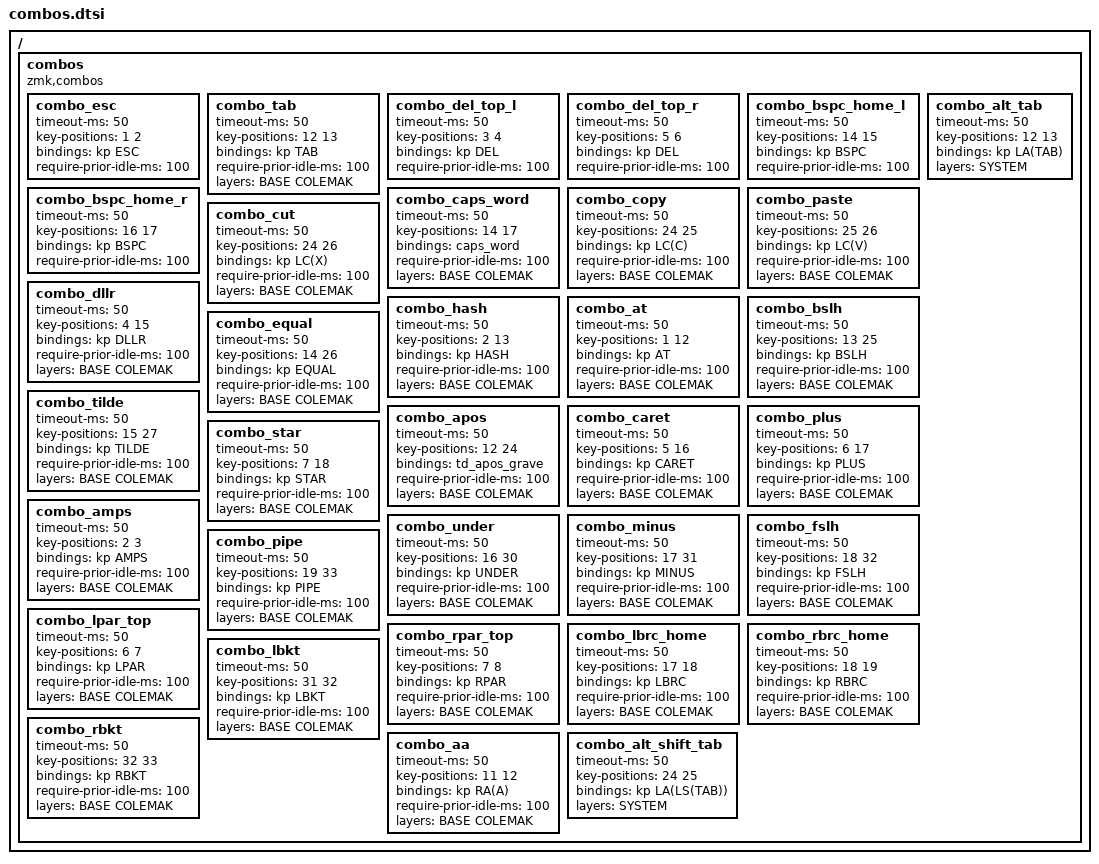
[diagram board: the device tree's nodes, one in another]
/*
 * Combo definitions for the KLOR keymap.
 * Include this file in klor.keymap via: #include "combos.dtsi"
 *
 * Key position map:
 *
 *  ┌─────┬─────┬─────┬─────┬─────┐                       ┌─────┬─────┬─────┬─────┬─────┐
 *  │  0  │  1  │  2  │  3  │  4  │                       │  5  │  6  │  7  │  8  │  9  │
 *  ├─────┼─────┼─────┼─────┼─────┤                       ├─────┼─────┼─────┼─────┼─────┤
 *  │ 11  │ 12  │ 13  │ 14  │ 15  │                       │ 16  │ 17  │ 18  │ 19  │ 20  │
 *  ├─────┼─────┼─────┼─────┼─────┼─────┐         ┌─────┼─────┼─────┼─────┼─────┼─────┤
 *  │ 23  │ 24  │ 25  │ 26  │ 27  │ 28  │         │ 29  │ 30  │ 31  │ 32  │ 33  │ 34  │
 *  └─────┴─────┴─────┼─────┼─────┼─────┘         └─────┼─────┼─────┼─────┴─────┴─────┘
 *                    │ 36  │ 37  │ 38  │ 39  40  │ 41  │ 42  │ 43  │
 *                    └─────┴─────┴─────┴─────────┴─────┴─────┴─────┘
 *
 * Note: outer pinky columns (10, 21, 22, 35) are &trans in all layers and excluded here.
 *
 * Layer policy:
 *   - ESC, BSPC, DEL combos are active on ALL layers (no layers restriction).
 *   - All other combos are BASE + COLEMAK (layers = <BASE COLEMAK>).
 */

/ {
    combos {
        compatible = "zmk,combos";

        // ── Navigation ─────────────────────────────────────────────────────────
        // W + E  →  Escape  [all layers]
        combo_esc {
            timeout-ms = <50>;
            key-positions = <1 2>;
            bindings = <&kp ESC>;
            require-prior-idle-ms = <100>;
        };

        // S + D  →  Tab  [BASE only]
        combo_tab {
            timeout-ms = <50>;
            key-positions = <12 13>;
            bindings = <&kp TAB>;
            require-prior-idle-ms = <100>;
            layers = <BASE COLEMAK>;
        };

        // R + T  →  Delete  [all layers]
        combo_del_top_l {
            timeout-ms = <50>;
            key-positions = <3 4>;
            bindings = <&kp DEL>;
            require-prior-idle-ms = <100>;
        };

        // Y + U  →  Delete  [all layers]
        combo_del_top_r {
            timeout-ms = <50>;
            key-positions = <5 6>;
            bindings = <&kp DEL>;
            require-prior-idle-ms = <100>;
        };

        // F + G  →  Backspace  [all layers]
        combo_bspc_home_l {
            timeout-ms = <50>;
            key-positions = <14 15>;
            bindings = <&kp BSPC>;
            require-prior-idle-ms = <100>;
        };

        // H + J  →  Backspace  [all layers]
        combo_bspc_home_r {
            timeout-ms = <50>;
            key-positions = <16 17>;
            bindings = <&kp BSPC>;
            require-prior-idle-ms = <100>;
        };

        // F + J  →  Caps Word  [BASE only]
        combo_caps_word {
            timeout-ms = <50>;
            key-positions = <14 17>;
            bindings = <&caps_word>;
            require-prior-idle-ms = <100>;
            layers = <BASE COLEMAK>;
        };

        // ── Clipboard ──────────────────────────────────────────────────────────
        // X + C  →  Copy  [BASE only]
        combo_copy {
            timeout-ms = <50>;
            key-positions = <24 25>;
            bindings = <&kp LC(C)>;
            require-prior-idle-ms = <100>;
            layers = <BASE COLEMAK>;
        };

        // C + V  →  Paste  [BASE only]
        combo_paste {
            timeout-ms = <50>;
            key-positions = <25 26>;
            bindings = <&kp LC(V)>;
            require-prior-idle-ms = <100>;
            layers = <BASE COLEMAK>;
        };

        // X + V  →  Cut  [BASE only]
        combo_cut {
            timeout-ms = <50>;
            key-positions = <24 26>;
            bindings = <&kp LC(X)>;
            require-prior-idle-ms = <100>;
            layers = <BASE COLEMAK>;
        };

        // ── Symbols: left side vertical (top → home) ───────────────────────────
        // T + G  →  $  [BASE only]
        combo_dllr {
            timeout-ms = <50>;
            key-positions = <4 15>;
            bindings = <&kp DLLR>;
            require-prior-idle-ms = <100>;
            layers = <BASE COLEMAK>;
        };

        // E + D  →  #  [BASE only]
        combo_hash {
            timeout-ms = <50>;
            key-positions = <2 13>;
            bindings = <&kp HASH>;
            require-prior-idle-ms = <100>;
            layers = <BASE COLEMAK>;
        };

        // W + S  →  @  [BASE only]
        combo_at {
            timeout-ms = <50>;
            key-positions = <1 12>;
            bindings = <&kp AT>;
            require-prior-idle-ms = <100>;
            layers = <BASE COLEMAK>;
        };

        // ── Symbols: left side vertical (home → bottom) ───────────────────────
        // D + C  →  backslash  [BASE only]
        combo_bslh {
            timeout-ms = <50>;
            key-positions = <13 25>;
            bindings = <&kp BSLH>;
            require-prior-idle-ms = <100>;
            layers = <BASE COLEMAK>;
        };

        // F + V  →  =  [BASE only]
        combo_equal {
            timeout-ms = <50>;
            key-positions = <14 26>;
            bindings = <&kp EQUAL>;
            require-prior-idle-ms = <100>;
            layers = <BASE COLEMAK>;
        };

        // G + B  →  ~  [BASE only]
        combo_tilde {
            timeout-ms = <50>;
            key-positions = <15 27>;
            bindings = <&kp TILDE>;
            require-prior-idle-ms = <100>;
            layers = <BASE COLEMAK>;
        };

        // S + X  →  ' (tap) / ` (double-tap)  [BASE only]
        combo_apos {
            timeout-ms = <50>;
            key-positions = <12 24>;
            bindings = <&td_apos_grave>;
            require-prior-idle-ms = <100>;
            layers = <BASE COLEMAK>;
        };

        // ── Symbols: right side vertical (top → home) ─────────────────────────
        // Y + H  →  ^  [BASE only]
        combo_caret {
            timeout-ms = <50>;
            key-positions = <5 16>;
            bindings = <&kp CARET>;
            require-prior-idle-ms = <100>;
            layers = <BASE COLEMAK>;
        };

        // U + J  →  +  [BASE only]
        combo_plus {
            timeout-ms = <50>;
            key-positions = <6 17>;
            bindings = <&kp PLUS>;
            require-prior-idle-ms = <100>;
            layers = <BASE COLEMAK>;
        };

        // I + K  →  *  [BASE only]
        combo_star {
            timeout-ms = <50>;
            key-positions = <7 18>;
            bindings = <&kp STAR>;
            require-prior-idle-ms = <100>;
            layers = <BASE COLEMAK>;
        };

        // E + R  →  &  [BASE only]
        combo_amps {
            timeout-ms = <50>;
            key-positions = <2 3>;
            bindings = <&kp AMPS>;
            require-prior-idle-ms = <100>;
            layers = <BASE COLEMAK>;
        };

        // ── Symbols: right side vertical (home → bottom) ──────────────────────
        // H + N  →  _  [BASE only]
        combo_under {
            timeout-ms = <50>;
            key-positions = <16 30>;
            bindings = <&kp UNDER>;
            require-prior-idle-ms = <100>;
            layers = <BASE COLEMAK>;
        };

        // J + M  →  -  [BASE only]
        combo_minus {
            timeout-ms = <50>;
            key-positions = <17 31>;
            bindings = <&kp MINUS>;
            require-prior-idle-ms = <100>;
            layers = <BASE COLEMAK>;
        };

        // K + ,  →  /  [BASE only]
        combo_fslh {
            timeout-ms = <50>;
            key-positions = <18 32>;
            bindings = <&kp FSLH>;
            require-prior-idle-ms = <100>;
            layers = <BASE COLEMAK>;
        };

        // L + .  →  |  [BASE only]
        combo_pipe {
            timeout-ms = <50>;
            key-positions = <19 33>;
            bindings = <&kp PIPE>;
            require-prior-idle-ms = <100>;
            layers = <BASE COLEMAK>;
        };

        // ── Brackets / parens: right side horizontal ───────────────────────────
        // U + I  →  (   [BASE only, top row]
        combo_lpar_top {
            timeout-ms = <50>;
            key-positions = <6 7>;
            bindings = <&kp LPAR>;
            require-prior-idle-ms = <100>;
            layers = <BASE COLEMAK>;
        };

        // I + O  →  )   [BASE only, top row]
        combo_rpar_top {
            timeout-ms = <50>;
            key-positions = <7 8>;
            bindings = <&kp RPAR>;
            require-prior-idle-ms = <100>;
            layers = <BASE COLEMAK>;
        };

        // J + K  →  {   [BASE only, home row]
        combo_lbrc_home {
            timeout-ms = <50>;
            key-positions = <17 18>;
            bindings = <&kp LBRC>;
            require-prior-idle-ms = <100>;
            layers = <BASE COLEMAK>;
        };

        // K + L  →  }   [BASE only, home row]
        combo_rbrc_home {
            timeout-ms = <50>;
            key-positions = <18 19>;
            bindings = <&kp RBRC>;
            require-prior-idle-ms = <100>;
            layers = <BASE COLEMAK>;
        };

        // M + ,  →  [   [BASE only, bottom row]
        combo_lbkt {
            timeout-ms = <50>;
            key-positions = <31 32>;
            bindings = <&kp LBKT>;
            require-prior-idle-ms = <100>;
            layers = <BASE COLEMAK>;
        };

        // , + .  →  ]   [BASE only, bottom row]
        combo_rbkt {
            timeout-ms = <50>;
            key-positions = <32 33>;
            bindings = <&kp RBKT>;
            require-prior-idle-ms = <100>;
            layers = <BASE COLEMAK>;
        };

        // ── Special characters ─────────────────────────────────────────────────
        // A + S  →  Å (A-ring)  [BASE only]
        combo_aa {
            timeout-ms = <50>;
            key-positions = <11 12>;
            bindings = <&kp RA(A)>;
            require-prior-idle-ms = <100>;
            layers = <BASE COLEMAK>;
        };

        // ── System layer combos ────────────────────────────────────────────────
        // S + D  →  Alt + Tab  [SYSTEM only]
        // No require-prior-idle-ms: the SYSTEM thumb key press would reset the idle timer
        combo_alt_tab {
            timeout-ms = <50>;
            key-positions = <12 13>;
            bindings = <&kp LA(TAB)>;
            layers = <SYSTEM>;
        };

        // X + C  →  Alt + Shift + Tab  [SYSTEM only]
        // No require-prior-idle-ms: the SYSTEM thumb key press would reset the idle timer
        combo_alt_shift_tab {
            timeout-ms = <50>;
            key-positions = <24 25>;
            bindings = <&kp LA(LS(TAB))>;
            layers = <SYSTEM>;
        };

    };
};
